# LAN9255ZMX018 register map
Vendor: Microchip
Registers are 32-bit, read-write, reset 0x0 unless marked. A register's access mark holds for its fields unless they carry their own. Addresses are absolute, and some are shared; only a register's first bit layout is shown; [hi:lo] are bit positions; {n}, {i} and the like mark numbered series; 'fields as' and 'values as' point back to an identical list.

## GMAC
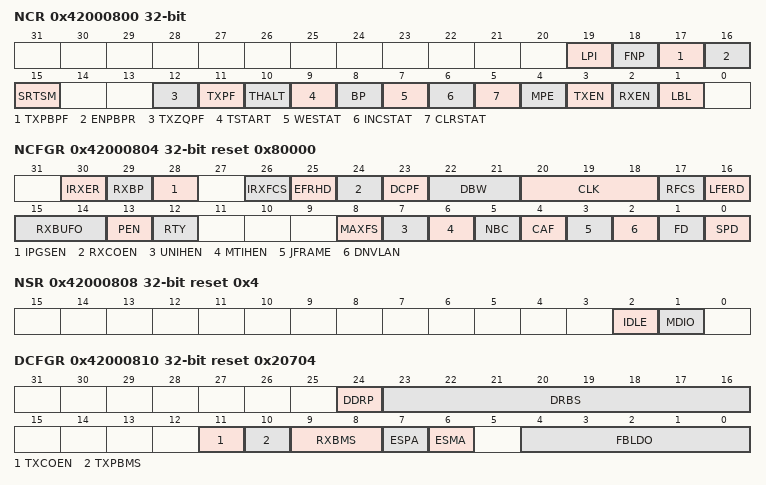
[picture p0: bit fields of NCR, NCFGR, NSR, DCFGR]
0x42000800 NCR
  [19] LPI — Low Power Idle Enable
  [18] FNP — Flush Next Packet
  [17] TXPBPF — Transmit PFC Priority-based Pause Frame
  [16] ENPBPR — Enable PFC Priority-based Pause Reception
  [15] SRTSM — Store Receive Time Stamp to Memory
  [12] TXZQPF — Transmit Zero Quantum Pause Frame
  [11] TXPF — Transmit Pause Frame
  [10] THALT — Transmit Halt
  [9] TSTART — Start Transmission
  [8] BP — Back pressure
  [7] WESTAT — Write Enable for Statistics Registers
  [6] INCSTAT — Increment Statistics Registers
  [5] CLRSTAT — Clear Statistics Registers
  [4] MPE — Management Port Enable
  [3] TXEN — Transmit Enable
  [2] RXEN — Receive Enable
  [1] LBL — Loop Back Local
0x42000804 NCFGR reset 0x80000
  [30] IRXER — Ignore IPG GRXER
  [29] RXBP — Receive Bad Preamble
  [28] IPGSEN — IP Stretch Enable
  [26] IRXFCS — Ignore RX FCS
  [25] EFRHD — Enable Frames Received in Half Duplex
  [24] RXCOEN — Receive Checksum Offload Enable
  [23] DCPF — Disable Copy of Pause Frames
  [22:21] DBW — Data Bus Width
  [20:18] CLK — MDC CLock Division
  [17] RFCS — Remove FCS
  [16] LFERD — Length Field Error Frame Discard
  [15:14] RXBUFO — Receive Buffer Offset
  [13] PEN — Pause Enable
  [12] RTY — Retry Test
  [8] MAXFS — 1536 Maximum Frame Size
  [7] UNIHEN — Unicast Hash Enable
  [6] MTIHEN — Multicast Hash Enable
  [5] NBC — No Broadcast
  [4] CAF — Copy All Frames
  [3] JFRAME — Jumbo Frame Size
  [2] DNVLAN — Discard Non-VLAN FRAMES
  [1] FD — Full Duplex
  [0] SPD — Speed
0x42000808 NSR ro reset 0x4
  [2] IDLE — PHY Management Logic Idle
  [1] MDIO — MDIO Input Status
0x4200080C UR
  [0] MII — MII Mode
0x42000810 DCFGR reset 0x20704
  [24] DDRP — DMA Discard Receive Packets
  [23:16] DRBS — DMA Receive Buffer Size
  [11] TXCOEN — Transmitter Checksum Generation Offload Enable
  [10] TXPBMS — Transmitter Packet Buffer Memory Size Select
  [9:8] RXBMS — Receiver Packet Buffer Memory Size Select
  [7] ESPA — Endian Swap Mode Enable for Packet Data Accesses
  [6] ESMA — Endian Swap Mode Enable for Management Descriptor Accesses
  [4:0] FBLDO — Fixed Burst Length for DMA Data Operations:
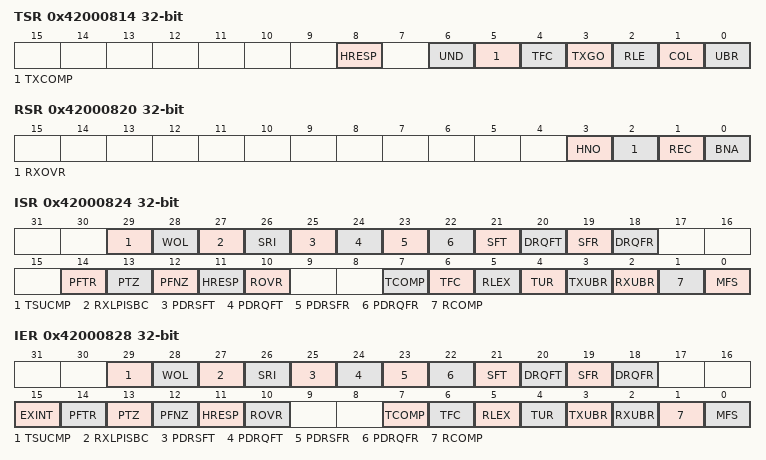
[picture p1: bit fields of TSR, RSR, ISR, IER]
0x42000814 TSR
  [8] HRESP — HRESP Not OK
  [6] UND — Transmit Underrun
  [5] TXCOMP — Transmit Complete
  [4] TFC — Transmit Frame Corruption Due to AHB Error
  [3] TXGO — Transmit Go
  [2] RLE — Retry Limit Exceeded
  [1] COL — Collision Occurred
  [0] UBR — Used Bit Read
0x42000818 RBQB
  [31:2] ADDR — Receive Buffer Queue Base Address
0x4200081C TBQB
  [31:2] ADDR — Transmit Buffer Queue Base Address
0x42000820 RSR
  [3] HNO — HRESP Not OK
  [2] RXOVR — Receive Overrun
  [1] REC — Frame Received
  [0] BNA — Buffer Not Available
0x42000824 ISR
  [29] TSUCMP — Tsu timer comparison
  [28] WOL — Wake On LAN
  [27] RXLPISBC — Enable RX LPI Indication
  [26] SRI — TSU Seconds Register Increment
  [25] PDRSFT — PDelay Response Frame Transmitted
  [24] PDRQFT — PDelay Request Frame Transmitted
  [23] PDRSFR — PDelay Response Frame Received
  [22] PDRQFR — PDelay Request Frame Received
  [21] SFT — PTP Sync Frame Transmitted
  [20] DRQFT — PTP Delay Request Frame Transmitted
  [19] SFR — PTP Sync Frame Received
  [18] DRQFR — PTP Delay Request Frame Received
  [14] PFTR — Pause Frame Transmitted
  [13] PTZ — Pause Time Zero
  [12] PFNZ — Pause Frame with Non-zero Pause Quantum Received
  [11] HRESP — HRESP Not OK
  [10] ROVR — Receive Overrun
  [7] TCOMP — Transmit Complete
  [6] TFC — Transmit Frame Corruption Due to AHB Error
  [5] RLEX — Retry Limit Exceeded
  [4] TUR — Transmit Underrun
  [3] TXUBR — TX Used Bit Read
  [2] RXUBR — RX Used Bit Read
  [1] RCOMP — Receive Complete
  [0] MFS — Management Frame Sent
0x42000828 IER wo reset not defined
  [29] TSUCMP — Tsu timer comparison
  [28] WOL — Wake On LAN
  [27] RXLPISBC — Enable RX LPI Indication
  [26] SRI — TSU Seconds Register Increment
  [25] PDRSFT — PDelay Response Frame Transmitted
  [24] PDRQFT — PDelay Request Frame Transmitted
  [23] PDRSFR — PDelay Response Frame Received
  [22] PDRQFR — PDelay Request Frame Received
  [21] SFT — PTP Sync Frame Transmitted
  [20] DRQFT — PTP Delay Request Frame Transmitted
  [19] SFR — PTP Sync Frame Received
  [18] DRQFR — PTP Delay Request Frame Received
  [15] EXINT — External Interrupt
  [14] PFTR — Pause Frame Transmitted
  [13] PTZ — Pause Time Zero
  [12] PFNZ — Pause Frame with Non-zero Pause Quantum Received
  [11] HRESP — HRESP Not OK
  [10] ROVR — Receive Overrun
  [7] TCOMP — Transmit Complete
  [6] TFC — Transmit Frame Corruption Due to AHB Error
  [5] RLEX — Retry Limit Exceeded or Late Collision
  [4] TUR — Transmit Underrun
  [3] TXUBR — TX Used Bit Read
  [2] RXUBR — RX Used Bit Read
  [1] RCOMP — Receive Complete
  [0] MFS — Management Frame Sent
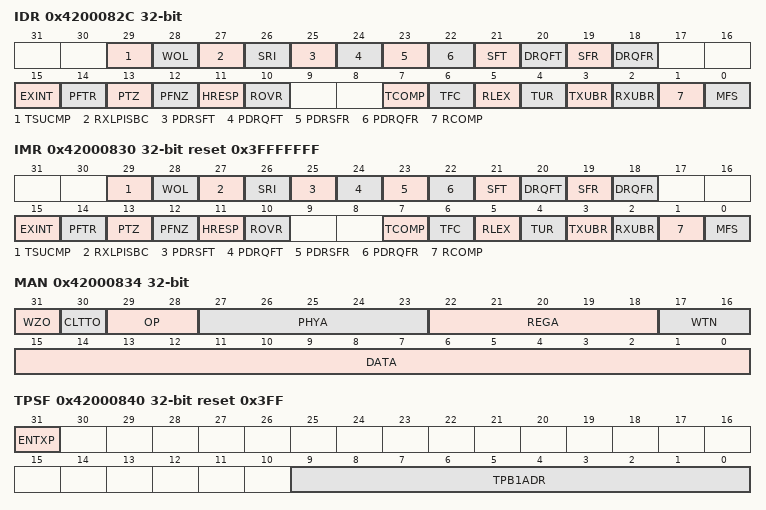
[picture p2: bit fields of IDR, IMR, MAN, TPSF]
0x4200082C IDR wo reset not defined
  fields as IER
0x42000830 IMR ro reset 0x3FFFFFFF
  [29] TSUCMP — Tsu timer comparison
  [28] WOL — Wake On Lan
  [27] RXLPISBC — Enable RX LPI Indication
  [26] SRI — TSU Seconds Register Increment
  [25] PDRSFT — PDelay Response Frame Transmitted
  [24] PDRQFT — PDelay Request Frame Transmitted
  [23] PDRSFR — PDelay Response Frame Received
  [22] PDRQFR — PDelay Request Frame Received
  [21] SFT — PTP Sync Frame Transmitted
  [20] DRQFT — PTP Delay Request Frame Transmitted
  [19] SFR — PTP Sync Frame Received
  [18] DRQFR — PTP Delay Request Frame Received
  [15] EXINT — External Interrupt
  [14] PFTR — Pause Frame Transmitted
  [13] PTZ — Pause Time Zero
  [12] PFNZ — Pause Frame with Non-zero Pause Quantum Received
  [11] HRESP — HRESP Not OK
  [10] ROVR — Receive Overrun
  [7] TCOMP — Transmit Complete
  [6] TFC — Transmit Frame Corruption Due to AHB Error
  [5] RLEX — Retry Limit Exceeded
  [4] TUR — Transmit Underrun
  [3] TXUBR — TX Used Bit Read
  [2] RXUBR — RX Used Bit Read
  [1] RCOMP — Receive Complete
  [0] MFS — Management Frame Sent
0x42000834 MAN
  [31] WZO — Write ZERO
  [30] CLTTO — Clause 22 Operation
  [29:28] OP — Operation
  [27:23] PHYA — PHY Address
  [22:18] REGA — Register Address
  [17:16] WTN — Write Ten
  [15:0] DATA — PHY Data
0x42000838 RPQ ro
  [15:0] RPQ — Received Pause Quantum
0x4200083C TPQ reset 0xFFFF
  [15:0] TPQ — Transmit Pause Quantum
0x42000840 TPSF reset 0x3FF
  [31] ENTXP — Enable TX partial store and forward operation
  [9:0] TPB1ADR — TX packet buffer address
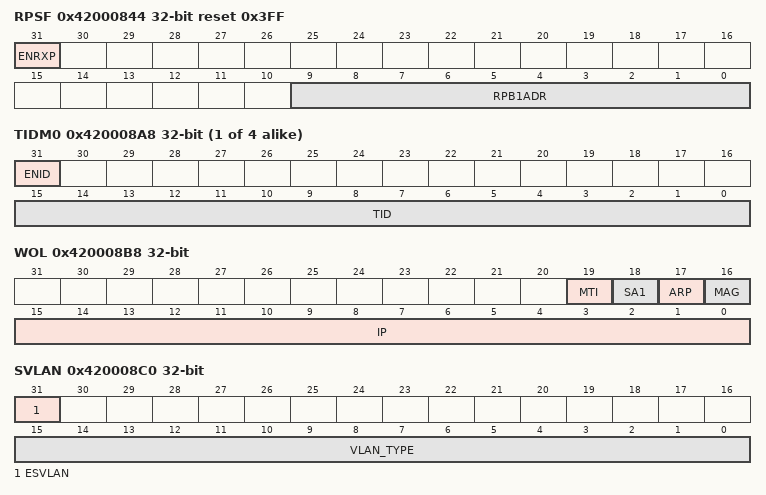
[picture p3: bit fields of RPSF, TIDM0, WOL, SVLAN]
0x42000844 RPSF reset 0x3FF
  [31] ENRXP — Enable RX partial store and forward operation
  [9:0] RPB1ADR — RX packet buffer address
0x42000848 RJFML reset 0x3FFF
  [13:0] FML — Frame Max Length
0x42000880 HRB
  [31:0] ADDR — Hash Address
0x42000884 HRT
  [31:0] ADDR — Hash Address
{0x42000888+8i} SA{i}SAB (i=0..3)
  [31:0] ADDR — Specific Address 1
{0x4200088C+8i} SA{i}SAT (i=0..3)
  [15:0] ADDR — Specific Address 1
{0x420008A8+4i} TIDM{i} (i=0..3)
  [31] ENID — Enable Copying of TID n Matched Frames
  [15:0] TID — Type ID Match n
0x420008B8 WOL
  [19] MTI — WOL LAN multicast
  [18] SA1 — WOL specific address reg 1
  [17] ARP — LAN ARP req
  [16] MAG — Event enable
  [15:0] IP — IP address
0x420008BC IPGS
  [15:0] FL — Frame Length
0x420008C0 SVLAN
  [31] ESVLAN — Enable Stacked VLAN Processing Mode
  [15:0] VLAN_TYPE — User Defined VLAN_TYPE Field
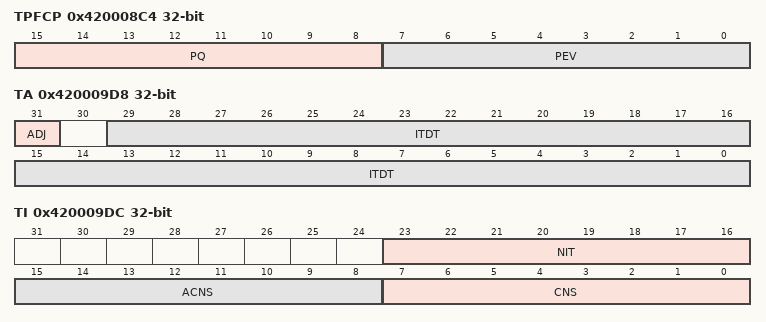
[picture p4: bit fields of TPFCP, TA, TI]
0x420008C4 TPFCP
  [15:8] PQ — Pause Quantum
  [7:0] PEV — Priority Enable Vector
0x420008C8 SAMB1
  [31:0] ADDR — Specific Address 1 Mask
0x420008CC SAMT1
  [15:0] ADDR — Specific Address 1 Mask
0x420008DC NSC
  [20:0] NANOSEC — 1588 Timer Nanosecond comparison value
0x420008E0 SCL
  [31:0] SEC — 1588 Timer Second comparison value
0x420008E4 SCH
  [15:0] SEC — 1588 Timer Second comparison value
0x420008E8 EFTSH ro
  [15:0] RUD — Register Update
0x420008EC EFRSH ro
  [15:0] RUD — Register Update
0x420008F0 PEFTSH ro
  [15:0] RUD — Register Update
0x420008F4 PEFRSH ro
  [15:0] RUD — Register Update
0x42000900 OTLO ro
  [31:0] TXO — Transmitted Octets
0x42000904 OTHI ro
  [15:0] TXO — Transmitted Octets
0x42000908 FT ro
  [31:0] FTX — Frames Transmitted without Error
0x4200090C BCFT ro
  [31:0] BFTX — Broadcast Frames Transmitted without Error
0x42000910 MFT ro
  [31:0] MFTX — Multicast Frames Transmitted without Error
0x42000914 PFT ro
  [15:0] PFTX — Pause Frames Transmitted Register
0x42000918 BFT64 ro
  [31:0] NFTX — 64 Byte Frames Transmitted without Error
0x4200091C TBFT127 ro
  [31:0] NFTX — 65 to 127 Byte Frames Transmitted without Error
0x42000920 TBFT255 ro
  [31:0] NFTX — 128 to 255 Byte Frames Transmitted without Error
0x42000924 TBFT511 ro
  [31:0] NFTX — 256 to 511 Byte Frames Transmitted without Error
0x42000928 TBFT1023 ro
  [31:0] NFTX — 512 to 1023 Byte Frames Transmitted without Error
0x4200092C TBFT1518 ro
  [31:0] NFTX — 1024 to 1518 Byte Frames Transmitted without Error
0x42000930 GTBFT1518 ro
  [31:0] NFTX — Greater than 1518 Byte Frames Transmitted without Error
0x42000934 TUR ro
  [9:0] TXUNR — Transmit Underruns
0x42000938 SCF ro
  [17:0] SCOL — Single Collision
0x4200093C MCF ro
  [17:0] MCOL — Multiple Collision
0x42000940 EC ro
  [9:0] XCOL — Excessive Collisions
0x42000944 LC ro
  [9:0] LCOL — Late Collisions
0x42000948 DTF ro
  [17:0] DEFT — Deferred Transmission
0x4200094C CSE ro
  [9:0] CSR — Carrier Sense Error
0x42000950 ORLO ro
  [31:0] RXO — Received Octets
0x42000954 ORHI ro
  [15:0] RXO — Received Octets
0x42000958 FR ro
  [31:0] FRX — Frames Received without Error
0x4200095C BCFR ro
  [31:0] BFRX — Broadcast Frames Received without Error
0x42000960 MFR ro
  [31:0] MFRX — Multicast Frames Received without Error
0x42000964 PFR ro
  [15:0] PFRX — Pause Frames Received Register
0x42000968 BFR64 ro
  [31:0] NFRX — 64 Byte Frames Received without Error
0x4200096C TBFR127 ro
  [31:0] NFRX — 65 to 127 Byte Frames Received without Error
0x42000970 TBFR255 ro
  [31:0] NFRX — 128 to 255 Byte Frames Received without Error
0x42000974 TBFR511 ro
  [31:0] NFRX — 256 to 511 Byte Frames Received without Error
0x42000978 TBFR1023 ro
  [31:0] NFRX — 512 to 1023 Byte Frames Received without Error
0x4200097C TBFR1518 ro
  [31:0] NFRX — 1024 to 1518 Byte Frames Received without Error
0x42000980 TMXBFR ro
  [31:0] NFRX — 1519 to Maximum Byte Frames Received without Error
0x42000984 UFR ro
  [9:0] UFRX — Undersize Frames Received
0x42000988 OFR ro
  [9:0] OFRX — Oversized Frames Received
0x4200098C JR ro
  [9:0] JRX — Jabbers Received
0x42000990 FCSE ro
  [9:0] FCKR — Frame Check Sequence Errors
0x42000994 LFFE ro
  [9:0] LFER — Length Field Frame Errors
0x42000998 RSE ro
  [9:0] RXSE — Receive Symbol Errors
0x4200099C AE ro
  [9:0] AER — Alignment Errors
0x420009A0 RRE ro
  [17:0] RXRER — Receive Resource Errors
0x420009A4 ROE ro
  [9:0] RXOVR — Receive Overruns
0x420009A8 IHCE ro
  [7:0] HCKER — IP Header Checksum Errors
0x420009AC TCE ro
  [7:0] TCKER — TCP Checksum Errors
0x420009B0 UCE ro
  [7:0] UCKER — UDP Checksum Errors
0x420009BC TISUBN
  [15:0] LSBTIR — Lower Significant Bits of Timer Increment
0x420009C0 TSH
  [15:0] TCS — Timer Count in Seconds
0x420009C8 TSSSL
  [31:0] VTS — Value of Timer Seconds Register Capture
0x420009CC TSSN
  [29:0] VTN — Value Timer Nanoseconds Register Capture
0x420009D0 TSL
  [31:0] TCS — Timer Count in Seconds
0x420009D4 TN
  [29:0] TNS — Timer Count in Nanoseconds
0x420009D8 TA wo
  [31] ADJ — Adjust 1588 Timer
  [29:0] ITDT — Increment/Decrement
0x420009DC TI
  [23:16] NIT — Number of Increments
  [15:8] ACNS — Alternative Count Nanoseconds
  [7:0] CNS — Count Nanoseconds
0x420009E0 EFTSL ro
  [31:0] RUD — Register Update
0x420009E4 EFTN ro
  [29:0] RUD — Register Update
0x420009E8 EFRSL ro
  [31:0] RUD — Register Update
0x420009EC EFRN ro
  [29:0] RUD — Register Update
0x420009F0 PEFTSL ro
  [31:0] RUD — Register Update
0x420009F4 PEFTN ro
  [29:0] RUD — Register Update
0x420009F8 PEFRSL ro
  [31:0] RUD — Register Update
0x420009FC PEFRN ro
  [29:0] RUD — Register Update
0x42000A70 RLPITR ro
  [15:0] RLPITR — Count number of times transition from rx normal idle to low power idle
0x42000A74 RLPITI ro
  [23:0] RLPITI — Increment once over 16 ahb clock when LPI indication bit 20 is set in rx mode
0x42000A78 TLPITR ro
  [15:0] TLPITR — Count number of times enable LPI tx bit 20 goes from low to high
0x42000A7C TLPITI ro
  [23:0] TLPITI — Increment once over 16 ahb clock when LPI indication bit 20 is set in tx mode
